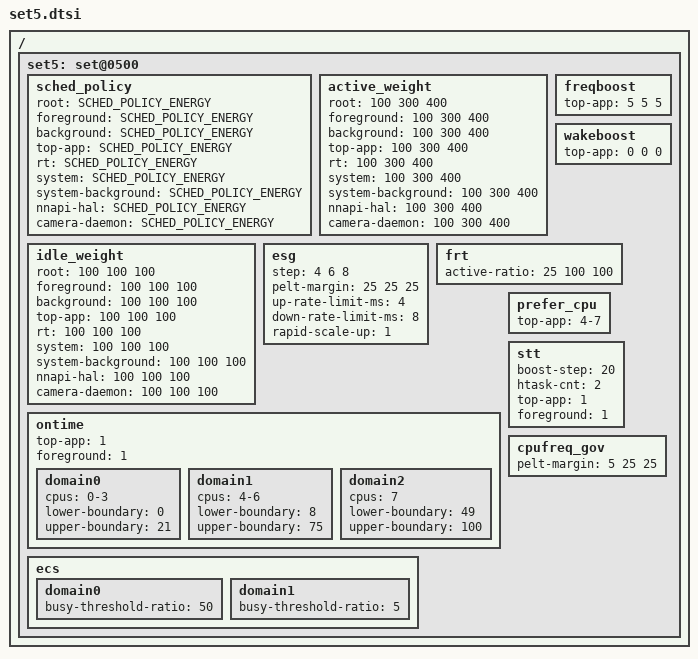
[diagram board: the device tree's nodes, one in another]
/ {
	/* camera mode - default */
	set5: set@0500 {
		/* schedudling policy */
		sched_policy {
			root			= <SCHED_POLICY_ENERGY>;
			foreground 		= <SCHED_POLICY_ENERGY>;
			background		= <SCHED_POLICY_ENERGY>;
			top-app			= <SCHED_POLICY_ENERGY>;
			rt			= <SCHED_POLICY_ENERGY>;
			system			= <SCHED_POLICY_ENERGY>;
			system-background	= <SCHED_POLICY_ENERGY>;
			nnapi-hal		= <SCHED_POLICY_ENERGY>;
			camera-daemon		= <SCHED_POLICY_ENERGY>;
		};

		/* weight (%) applied to active cpu's efficiency */
		active_weight {			/* LIT MED BIG */
			root			= <100 300 400>;
			foreground		= <100 300 400>;
			background		= <100 300 400>;
			top-app			= <100 300 400>;
			rt			= <100 300 400>;
			system			= <100 300 400>;
			system-background	= <100 300 400>;
			nnapi-hal		= <100 300 400>;
			camera-daemon		= <100 300 400>;
		};

		/* weight (%) applied to idle cpu's efficiency */
		idle_weight {			/* LIT MED BIG */
			root			= <100 100 100>;
			foreground		= <100 100 100>;
			background		= <100 100 100>;
			top-app			= <100 100 100>;
			rt			= <100 100 100>;
			system			= <100 100 100>;
			system-background	= <100 100 100>;
			nnapi-hal		= <100 100 100>;
			camera-daemon		= <100 100 100>;
		};

		/* Boosting margin applied to frequency selection */
		freqboost {			/* LIT MED BIG */
			top-app			= <  5   5   5>;
		};

		/* Boosting margin for waking up task */
		wakeboost {			/* LIT MED BIG */
			top-app			= < 0  0  0>;
		};

		/* gov-data used by ESG */
		esg {				/* LIT MED BIG */
			step			= <  4   6   8>;
			pelt-margin		= < 25  25  25>;

			up-rate-limit-ms 	= <4>;
			down-rate-limit-ms 	= <8>;
			rapid-scale-up 		= <1>;
		};

		frt {	   	     		/* LIT MED BIG */
			active-ratio		= < 25 100 100>;
		};

		/* Ontime Migration */
		ontime {
			top-app		= <1>;
			foreground	= <1>;

			domain0 {
				cpus = "0-3";
				lower-boundary = <0>;
				upper-boundary = <21>;
			};
			domain1 {
				cpus = "4-6";
				lower-boundary = <8>;
				upper-boundary = <75>;
			};
			domain2 {
				cpus = "7";
				lower-boundary = <49>;
				upper-boundary = <100>;
			};
		};

		ecs {
			domain0 {
				busy-threshold-ratio = <50>;
			};
			domain1 {
				busy-threshold-ratio = <5>;
			};
		};

		prefer_cpu {
			top-app = "4-7";
		};

		stt {
			boost-step		= <20>;
			htask-cnt		= <2>;
			top-app			= <1>;
			foreground		= <1>;
		};

		cpufreq_gov {			/* LIT MED BIG */
			pelt-margin		= <  5   25   25 >;
		};
	};
};
